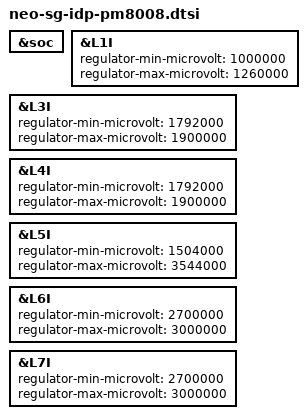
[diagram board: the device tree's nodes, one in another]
#include "neo-sg-idp.dtsi"
#include "neo-pm8008.dtsi"

&soc {
};

&L1I {
	regulator-min-microvolt = <1000000>;
	regulator-max-microvolt = <1260000>;
};

&L3I {
	regulator-min-microvolt = <1792000>;
	regulator-max-microvolt = <1900000>;
};

&L4I {
	regulator-min-microvolt = <1792000>;
	regulator-max-microvolt = <1900000>;
};

&L5I {
	regulator-min-microvolt = <1504000>;
	regulator-max-microvolt = <3544000>;
};

&L6I {
	regulator-min-microvolt = <2700000>;
	regulator-max-microvolt = <3000000>;
};

&L7I {
	regulator-min-microvolt = <2700000>;
	regulator-max-microvolt = <3000000>;
};
